# cmem7 register map
File version: 1.0
Registers are 32-bit, read-write, reset 0x0 unless marked. A register's access mark holds for its fields unless they carry their own. Offsets are from the block's base; [hi:lo] are bit positions; 'fields as' and 'values as' point back to an identical list.

## I2C0
Base 0x41003000
Same registers: I2C1 0x4100A000
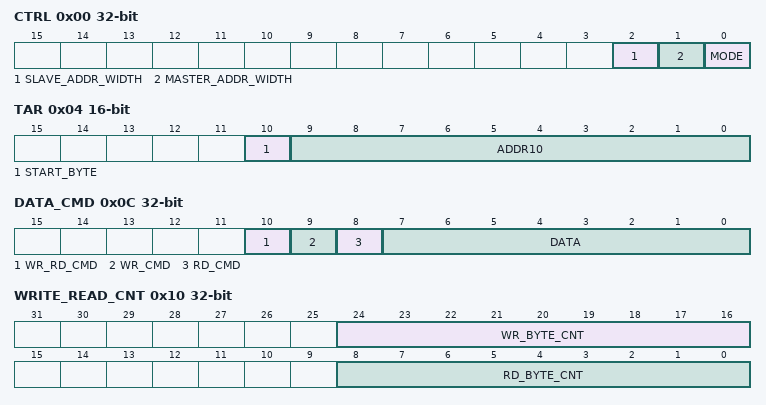
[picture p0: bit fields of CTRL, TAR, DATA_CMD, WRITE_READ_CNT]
0x00 CTRL — control Register
  [2] SLAVE_ADDR_WIDTH — 7- or 10-bits address width as a slave
    0=SLAVE_ADDR_WIDTH_7BIT (7-bits address as a slave); 1=SLAVE_ADDR_WIDTH_10BIT (10-bits address as a slave)
  [1] MASTER_ADDR_WIDTH — 7- or 10-bits address as a master
    0=MASTER_ADDR_WIDTH_7BIT (7-bits address as a master); 1=MASTER_ADDR_WIDTH_10BIT (10-bits address as a master)
  [0] MODE — master or slave mode
    0=MODE_SLAVE (slave mode); 1=MODE_MASTER (master mode)
0x04 TAR 16-bit (reset mask 0x3FF) — target address Register
  [10] START_BYTE — Enable start Byte for each transfer
  [9:0] ADDR10 — 7- or 10-bits address
0x08 SAR 16-bit — slave address Register
  [9:0] ADDR10 — 7- or 10-bits address
0x0C DATA_CMD (reset mask 0x3FF) — I2C transfer data/command entry
  [10] WR_RD_CMD wo — write and read command for master mode only
  [9] WR_CMD wo — write command for master mode only
  [8] RD_CMD wo — read command for master mode only, write 0 if slave mode
  [7:0] DATA — 8-bits data
0x10 WRITE_READ_CNT — I2C write and read data byte counter Register
  [24:16] WR_BYTE_CNT — Decide the number of byte to send as a master-transmitter
  [8:0] RD_BYTE_CNT — Decide the number of bytes read back as a master-receiver
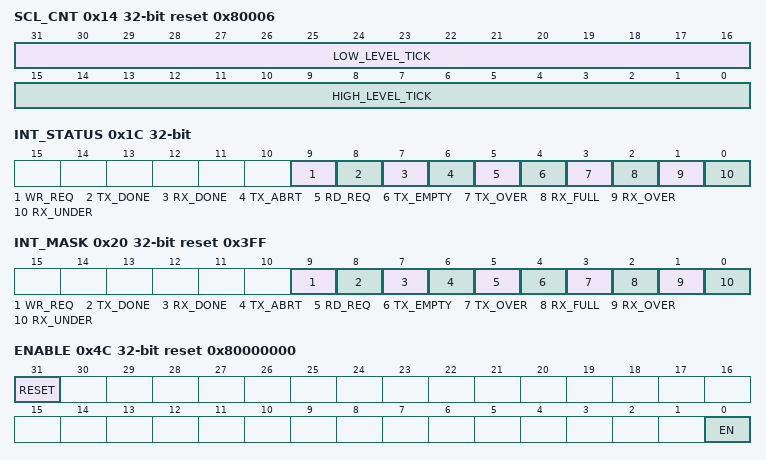
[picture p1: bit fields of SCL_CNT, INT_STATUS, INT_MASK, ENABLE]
0x14 SCL_CNT reset 0x80006 — I2C clk pulse counter
  [31:16] LOW_LEVEL_TICK — the SCL clock low-period count
  [15:0] HIGH_LEVEL_TICK — the SCL clock high-period count
0x1C INT_STATUS ro — I2C interrupt sources
  [9] WR_REQ — write request
  [8] TX_DONE — transmit done
  [7] RX_DONE — receive done
  [6] TX_ABRT — transmit abortion
  [5] RD_REQ — read request
  [4] TX_EMPTY — transmit is empty
  [3] TX_OVER — transmit overflow
  [2] RX_FULL — receiver is full
  [1] RX_OVER — receiver overflow
  [0] RX_UNDER — receiver underflow
0x20 INT_MASK reset 0x3FF — I2C interrupt mask register
  fields as INT_STATUS
0x28 RX_TL — I2C receive FIFO threshold
  [4:0] THRESHOLD — FIFO threashold
0x2C TX_TL — I2C transmit FIFO threshold
  [4:0] THRESHOLD — FIFO threashold
0x30 CLR_ALL_INT ro — I2C clear all interrupt register
  [0] CLEAR — Read this register to clear all individual interrupts
0x34 CLR_RX_UNDER ro — I2C clear RX_UNDER interrupt
  [0] CLEAR — Read this register to clear the RX_UNDER interrupt (bit 19) of the I2C_STATUS register
0x38 CLR_RX_OVER ro — I2C clear RX_OVER interrupt
  [0] CLEAR — Read this register to clear the RX_OVER interrupt (bit 20) of the I2C_STATUS register
0x3C CLR_TX_OVER ro — I2C clear TX_OVER interrupt
  [0] CLEAR — Read this register to clear the TX_OVER interrupt (bit 22) of the I2C_STATUS register
0x40 CLR_RD_REQ ro — I2C clear RD_REQ interrupt
  [0] CLEAR — Read this register to clear the RD_REQ interrupt (bit 24) of the I2C_STATUS register
0x44 CLR_TX_ABRT ro — I2C clear TX_ABRT interrupt
  [0] CLEAR — Read this register to clear the TX_ABRT interrupts (bit 25 , bit 18, bit 17, bit 16 and bit 15) of the I2C_STATUS register.
0x48 CLR_RX_DONE ro — I2C clear RX_DONE interrupt
  [0] CLEAR — Read this register to clear the RX_DONE interrupt (bit 26) of the I2C_STATUS register
0x4C ENABLE reset 0x80000000 — I2C enable register
  [31] RESET — TX and RX FIFO are held in an erased state( flushed) and all interrupts deserted
  [0] EN — enable device
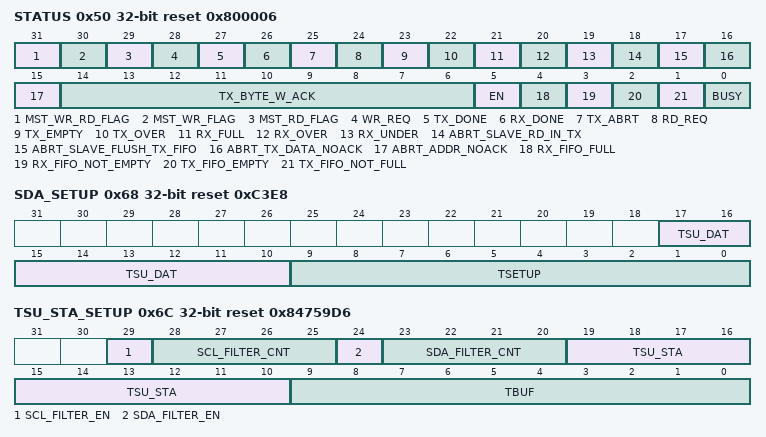
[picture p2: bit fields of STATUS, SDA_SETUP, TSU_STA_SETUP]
0x50 STATUS ro reset 0x800006 — I2C status register
  [31] MST_WR_RD_FLAG — Master is executing write-read command
  [30] MST_WR_FLAG — Master is executing read command
  [29] MST_RD_FLAG — Master is executing read command
  [28] WR_REQ — write request is received
  [27] TX_DONE — transmit is done
  [26] RX_DONE — receive is done
  [25] TX_ABRT — transmit is abort
  [24] RD_REQ — read request is received
  [23] TX_EMPTY — transmit is empty
  [22] TX_OVER — transmit is overflow
  [21] RX_FULL — receiver is full
  [20] RX_OVER — receiver is overflow
  [19] RX_UNDER — receiver is underflow
  [18] ABRT_SLAVE_RD_IN_TX — When the processor side responds to a slave mode request for data to be transmitted to a remote master and user writes a 1 in CMD (bit 8) of I2C_DATA_CMD register
  [17] ABRT_SLAVE_FLUSH_TX_FIFO — Slave has received a read command and some data exists in the TX FIFO so the slave issues a TX_ABRT interrupt to flush old data in TX FIFO
  [16] ABRT_TX_DATA_NOACK — the data sent was not acknowledged by any slave as a master
  [15] ABRT_ADDR_NOACK — the address sent was not acknowledged by any slave as a master
  [14:6] TX_BYTE_W_ACK — Number of bytes sent to slave with acknowledge during the last write transaction as a master-transmitter only
  [5] EN — I2C is enabled
  [4] RX_FIFO_FULL — receive FIFO is full
  [3] RX_FIFO_NOT_EMPTY — receive FIFO is not empty
  [2] TX_FIFO_EMPTY — transmit FIFO is empty
  [1] TX_FIFO_NOT_FULL — transmit FIFO is not full
  [0] BUSY — I2C busy Status
0x54 TX_FIFO_LEVEL ro — I2C transmit FIFO level
  [4:0] LEVEL — FIFO level
0x58 RX_FIFO_LEVEL ro — I2C receive FIFO level
  [4:0] LEVEL — FIFO level
0x60 SLAVE_NACK wo reset not defined — I2C slave send a data NACK
  [0] NACK — data NACK
0x68 SDA_SETUP reset 0xC3E8 — I2C SDA setup timer
  [17:10] TSU_DAT — This counter defines the constrain of TSU:DAT: 250ns (or 100ns) / INPUT_CLK_PERIOD
  [9:0] TSETUP — This counter defines the max value of the following constrains:THD:STA TSU:STO,TSETUP: T / INPUT_CLK_PERIOD
0x6C TSU_STA_SETUP reset 0x84759D6 — I2C Tsu_sta and Tbuf_free timer
  [29] SCL_FILTER_EN — SCL filter enable bit
  [28:25] SCL_FILTER_CNT — SCL filter count
  [24] SDA_FILTER_EN — SDA filter enable bit
  [23:20] SDA_FILTER_CNT — SDA filter count
  [19:10] TSU_STA — This counter defines the constrain of Tsu:sta, Tsu:sta : Tsu:sta / INPUT_CLK_PERIOD
  [9:0] TBUF — This counter defines the constrain of bus free interval: Tbuf, Tbuf : Tbus_free / INPUT_CLK_PERIOD
0x70 CLR_TX_DONE ro reset not defined — I2C clear TX_DONE interrupt
  [0] CLEAR — Read this register to clear the TX_DONE interrupt (bit 27) of the I2C_STATUS register
